AUTOSAR XML (schema 4.0)
standard types defined: float32, float64, sint16, sint32, sint8, uint16, uint32, uint8, void, boolean
package /ImplDataTypes
  impl type MultiStateBtnType: implementation-data-type=uint8, type-emitter=RTE
  impl type StepMotorStepType: implementation-data-type=uint8, type-emitter=RTE
package /MappingSets
  data type mapping set MappingSet
package /PortInterfaces/ClientServer
  client server interface CsIf_StepMotor
    operation Move
      arg step: type=StepMotorStepType, direction=IN
package /PortInterfaces/SenderReceiver
  sender receiver interface SrIf_SeatCtrlBtns
    data HeightBtnState: type=MultiStateBtnType
    data InclineBtnState: type=MultiStateBtnType
    data SlideBtnState: type=MultiStateBtnType
  sender receiver interface SrIf_SeatCtrlData
    data Height: type=uint8
    data Incline: type=uint8
    data Slide: type=uint8
package /SoftwareComponents
  5 x swc implementation, all with programming-language=C, sw-version=1.0.0, vendor-id=255:
    Impl_SWC_HMI: behavior=Ibhv_SWC_HMI
      code-descriptors:
        code Code: artifact-descriptors=autosar-engineering-object={short-label=SWC.c, category=SWSRC}
      resource consumption ResourceConsumption
    Impl_SWC_HeightMotor: behavior=Ibhv_SWC_HeightMotor
      code-descriptors:
        code Code: artifact-descriptors=autosar-engineering-object={short-label=SWC.c, category=SWSRC}
      resource consumption ResourceConsumption
    Impl_SWC_InclineMotor: behavior=Ibhv_SWC_InclineMotor
      code-descriptors:
        code Code: artifact-descriptors=autosar-engineering-object={short-label=SWC.c, category=SWSRC}
      resource consumption ResourceConsumption
    Impl_SWC_SeatManager: behavior=Ibhv_SWC_SeatManager
      code-descriptors:
        code Code: artifact-descriptors=autosar-engineering-object={short-label=SWC.c, category=SWSRC}
      resource consumption ResourceConsumption
    Impl_SWC_SlideMotor: behavior=Ibhv_SWC_SlideMotor
      code-descriptors:
        code Code: artifact-descriptors=autosar-engineering-object={short-label=SWC.c, category=SWSRC}
      resource consumption ResourceConsumption
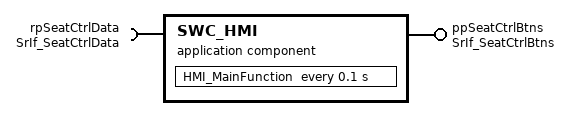
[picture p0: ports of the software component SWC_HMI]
  application sw component type SWC_HMI
    provide port ppSeatCtrlBtns: provided-interface=SrIf_SeatCtrlBtns
    require port rpSeatCtrlData: required-interface=SrIf_SeatCtrlData
    behavior Ibhv_SWC_HMI: data-type-mapping=MappingSet, handle-termination-and-restart=NO-SUPPORT
      timing event TE_HMI_MainFunction_100ms: start-on-event=HMI_MainFunction, period=0.1
      runnable HMI_MainFunction
        data-receive-point-by-arguments:
          access DRP_rpSeatCtrlData_DE_Height: accessed-variable=rpSeatCtrlData.Height
          access DRP_rpSeatCtrlData_DE_Incline: accessed-variable=rpSeatCtrlData.Incline
          access DRP_rpSeatCtrlData_DE_Slide: accessed-variable=rpSeatCtrlData.Slide
        data-send-points:
          access DSP_ppSeatCtrlBtns_DE_HeightBtnState: accessed-variable=ppSeatCtrlBtns.HeightBtnState
          access DSP_ppSeatCtrlBtns_DE_InclineBtnState: accessed-variable=ppSeatCtrlBtns.InclineBtnState
          access DSP_ppSeatCtrlBtns_DE_SlideBtnState: accessed-variable=ppSeatCtrlBtns.SlideBtnState
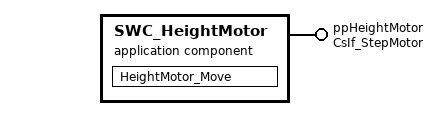
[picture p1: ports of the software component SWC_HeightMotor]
  application sw component type SWC_HeightMotor
    provide port ppHeightMotor: provided-interface=CsIf_StepMotor
    behavior Ibhv_SWC_HeightMotor: data-type-mapping=MappingSet, handle-termination-and-restart=NO-SUPPORT
      operation invoked event OIE_ppHeightMotor_Move: start-on-event=HeightMotor_Move, operation=ppHeightMotor.Move
      runnable HeightMotor_Move
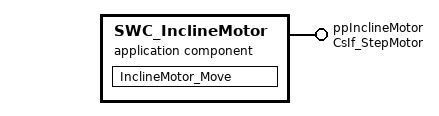
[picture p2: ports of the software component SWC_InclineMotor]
  application sw component type SWC_InclineMotor
    provide port ppInclineMotor: provided-interface=CsIf_StepMotor
    behavior Ibhv_SWC_InclineMotor: data-type-mapping=MappingSet, handle-termination-and-restart=NO-SUPPORT
      operation invoked event OIE_ppInclineMotor_Move: start-on-event=InclineMotor_Move, operation=ppInclineMotor.Move
      runnable InclineMotor_Move
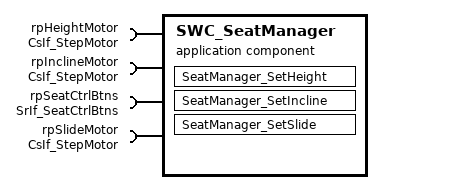
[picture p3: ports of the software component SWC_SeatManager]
  application sw component type SWC_SeatManager
    4 x require port:
      rpHeightMotor: required-interface=CsIf_StepMotor
      rpInclineMotor: required-interface=CsIf_StepMotor
      rpSeatCtrlBtns: required-interface=SrIf_SeatCtrlBtns
      rpSlideMotor: required-interface=CsIf_StepMotor
    behavior Ibhv_SWC_SeatManager: data-type-mapping=MappingSet, handle-termination-and-restart=NO-SUPPORT
      data received event DRE_rpSeatCtrlBtns_DE_HeightBtnState: start-on-event=SeatManager_SetHeight, data=rpSeatCtrlBtns.HeightBtnState
      data received event DRE_rpSeatCtrlBtns_DE_InclineBtnState: start-on-event=SeatManager_SetIncline, data=rpSeatCtrlBtns.InclineBtnState
      data received event DRE_rpSeatCtrlBtns_DE_SlideBtnState: start-on-event=SeatManager_SetSlide, data=rpSeatCtrlBtns.SlideBtnState
      runnable SeatManager_SetHeight
        data-receive-point-by-arguments:
          access DRP_rpSeatCtrlBtns_DE_HeightBtnState: accessed-variable=rpSeatCtrlBtns.HeightBtnState
        sync call SCP_rpHeightMotor_Move: operation=rpHeightMotor.Move, timeout=0.0
      runnable SeatManager_SetIncline
        data-receive-point-by-arguments:
          access DRP_rpSeatCtrlBtns_DE_InclineBtnState: accessed-variable=rpSeatCtrlBtns.InclineBtnState
        sync call SCP_rpInclineMotor_Move: operation=rpInclineMotor.Move, timeout=0.0
      runnable SeatManager_SetSlide
        data-receive-point-by-arguments:
          access DRP_rpSeatCtrlBtns_DE_SlideBtnState: accessed-variable=rpSeatCtrlBtns.SlideBtnState
        sync call SCP_rpSlideMotor_Move: operation=rpSlideMotor.Move, timeout=0.0
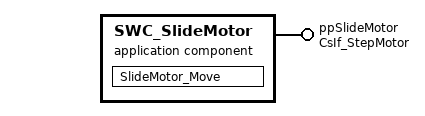
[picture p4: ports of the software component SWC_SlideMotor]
  application sw component type SWC_SlideMotor
    provide port ppSlideMotor: provided-interface=CsIf_StepMotor
    behavior Ibhv_SWC_SlideMotor: data-type-mapping=MappingSet, handle-termination-and-restart=NO-SUPPORT
      operation invoked event OIE_ppSlideMotor_Move: start-on-event=SlideMotor_Move, operation=ppSlideMotor.Move
      runnable SlideMotor_Move
package /Compositions
  composition sw component type Task1Composition
    5 x component:
      SWC_HMI: type=SWC_HMI
      SWC_HeightMotor: type=SWC_HeightMotor
      SWC_InclineMotor: type=SWC_InclineMotor
      SWC_SeatManager: type=SWC_SeatManager
      SWC_SlideMotor: type=SWC_SlideMotor
    connect SWC_HMI.ppSeatCtrlBtns -> SWC_SeatManager.rpSeatCtrlBtns
    connect SWC_HeightMotor.ppHeightMotor -> SWC_SeatManager.rpHeightMotor
    connect SWC_InclineMotor.ppInclineMotor -> SWC_SeatManager.rpInclineMotor
    connect SWC_SlideMotor.ppSlideMotor -> SWC_SeatManager.rpSlideMotor
